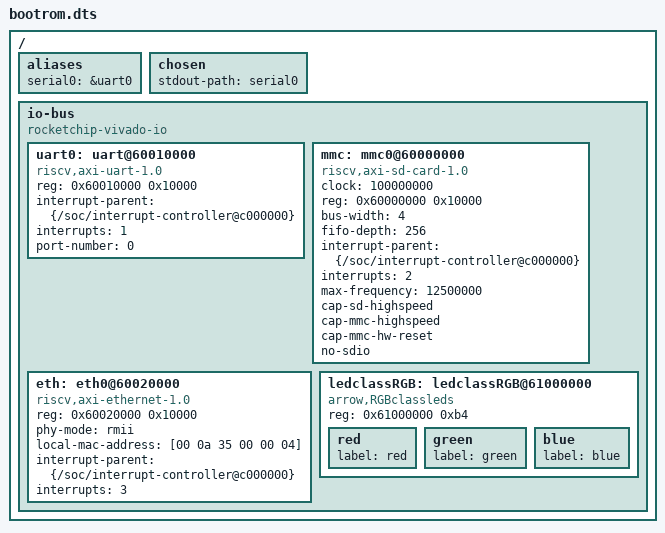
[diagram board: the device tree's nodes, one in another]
/ {

    aliases {
        serial0 = &uart0;
    };

    chosen {
        stdout-path = "serial0";
    };

    io-bus {
        #address-cells = <1>;
        #size-cells = <1>;
        compatible = "rocketchip-vivado-io", "simple-bus";
        ranges;

        uart0: uart@60010000 {
            compatible = "riscv,axi-uart-1.0";
            reg = <0x60010000 0x10000>;
            interrupt-parent = <&{/soc/interrupt-controller@c000000}>;
            interrupts = <1>;
            port-number = <0>;
        };

        mmc: mmc0@60000000 {
            compatible = "riscv,axi-sd-card-1.0";
            clock = <100000000>;
            reg = <0x60000000 0x10000>;
            bus-width = <4>;
            fifo-depth = <256>;
            interrupt-parent = <&{/soc/interrupt-controller@c000000}>;
            interrupts = <2>;
            max-frequency = <12500000>;
            cap-sd-highspeed;
            cap-mmc-highspeed;
            cap-mmc-hw-reset;
            no-sdio;
        };

        eth: eth0@60020000 {
            compatible = "riscv,axi-ethernet-1.0";
            reg = <0x60020000 0x10000>;
            phy-mode = "rmii";
            local-mac-address = [00 0a 35 00 00 04];
            interrupt-parent = <&{/soc/interrupt-controller@c000000}>;
            interrupts = <3>;
        };
		
		//sfp0: sfp0@20000000 {		
		//	compatible = "riscv,axi-sfp-1.0";
		//	reg = <0x20000000 0x20000000>;
		//};
		
		ledclassRGB: ledclassRGB@61000000{
	
			compatible = "arrow,RGBclassleds";
			reg = <0x61000000 0xb4>;
			pinctrl-names = "default";

			red {
				label = "red";
			};

			green {
				label = "green";
			};

			blue {
				label = "blue";
				//linux,default-trigger = "heartbeat";
			};
		};
    };

};
